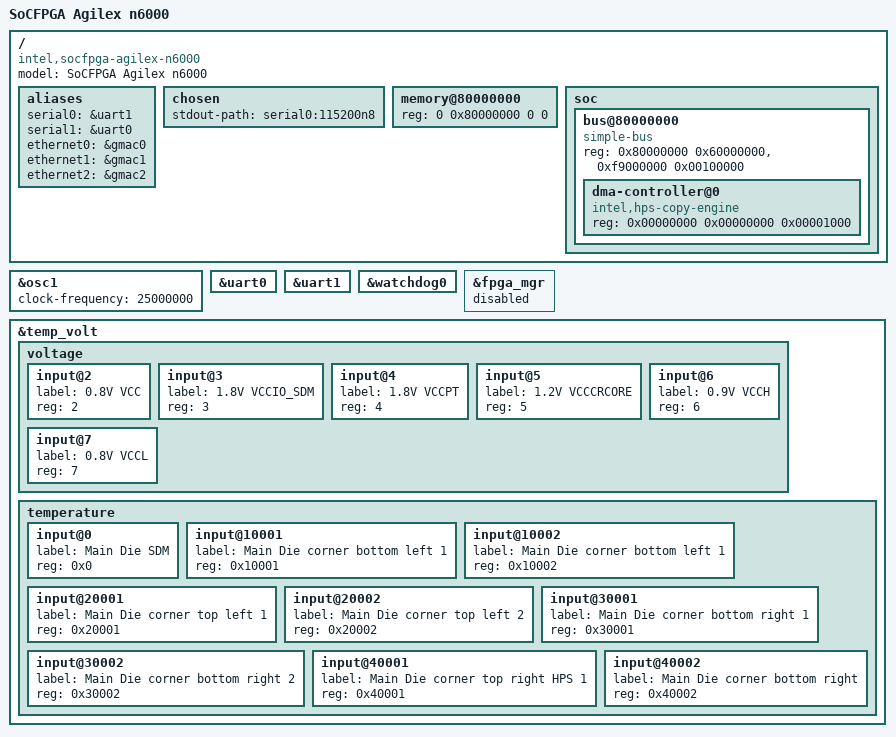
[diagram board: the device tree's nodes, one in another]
// SPDX-License-Identifier: GPL-2.0
/*
 * Copyright (C) 2021-2022, Intel Corporation
 */
#include "socfpga_agilex.dtsi"

/ {
	model = "SoCFPGA Agilex n6000";
	compatible = "intel,socfpga-agilex-n6000", "intel,socfpga-agilex";

	aliases {
		serial0 = &uart1;
		serial1 = &uart0;
		ethernet0 = &gmac0;
		ethernet1 = &gmac1;
		ethernet2 = &gmac2;
	};

	chosen {
		stdout-path = "serial0:115200n8";
	};

	memory@80000000 {
		device_type = "memory";
		/* We expect the bootloader to fill in the reg */
		reg = <0 0x80000000 0 0>;
	};

	soc {
		bus@80000000 {
			compatible = "simple-bus";
			reg = <0x80000000 0x60000000>,
				<0xf9000000 0x00100000>;
			reg-names = "axi_h2f", "axi_h2f_lw";
			#address-cells = <2>;
			#size-cells = <1>;
			ranges = <0x00000000 0x00000000 0xf9000000 0x00001000>;

			dma-controller@0 {
				compatible = "intel,hps-copy-engine";
				reg = <0x00000000 0x00000000 0x00001000>;
				#dma-cells = <1>;
			};
		};
	};
};

&osc1 {
	clock-frequency = <25000000>;
};

&uart0 {
	status = "okay";
};

&uart1 {
	status = "okay";
};

&watchdog0 {
	status = "okay";
};

&fpga_mgr {
	status = "disabled";
};

&temp_volt {
	voltage {
		#address-cells = <1>;
		#size-cells = <0>;
		input@2 {
			label = "0.8V VCC";
			reg = <2>;
		};

		input@3 {
			label = "1.8V VCCIO_SDM";
			reg = <3>;
		};

		input@4 {
			label = "1.8V VCCPT";
			reg = <4>;
		};

		input@5 {
			label = "1.2V VCCCRCORE";
			reg = <5>;
		};

		input@6 {
			label = "0.9V VCCH";
			reg = <6>;
		};

		input@7 {
			label = "0.8V VCCL";
			reg = <7>;
		};
	};

	temperature {
		#address-cells = <1>;
		#size-cells = <0>;

		input@0 {
			label = "Main Die SDM";
			reg = <0x0>;
		};

		input@10001 {
			label = "Main Die corner bottom left 1";
			reg = <0x10001>;
		};

		input@10002 {
			label = "Main Die corner bottom left 1";
			reg = <0x10002>;
		};

		input@20001 {
			label = "Main Die corner top left 1";
			reg = <0x20001>;
		};

		input@20002 {
			label = "Main Die corner top left 2";
			reg = <0x20002>;
		};

		input@30001 {
			label = "Main Die corner bottom right 1";
			reg = <0x30001>;
		};

		input@30002 {
			label = "Main Die corner bottom right 2";
			reg = <0x30002>;
		};

		input@40001 {
			label = "Main Die corner top right HPS 1";
			reg = <0x40001>;
		};

		input@40002 {
			label = "Main Die corner bottom right";
			reg = <0x40002>;
		};
	};
};
